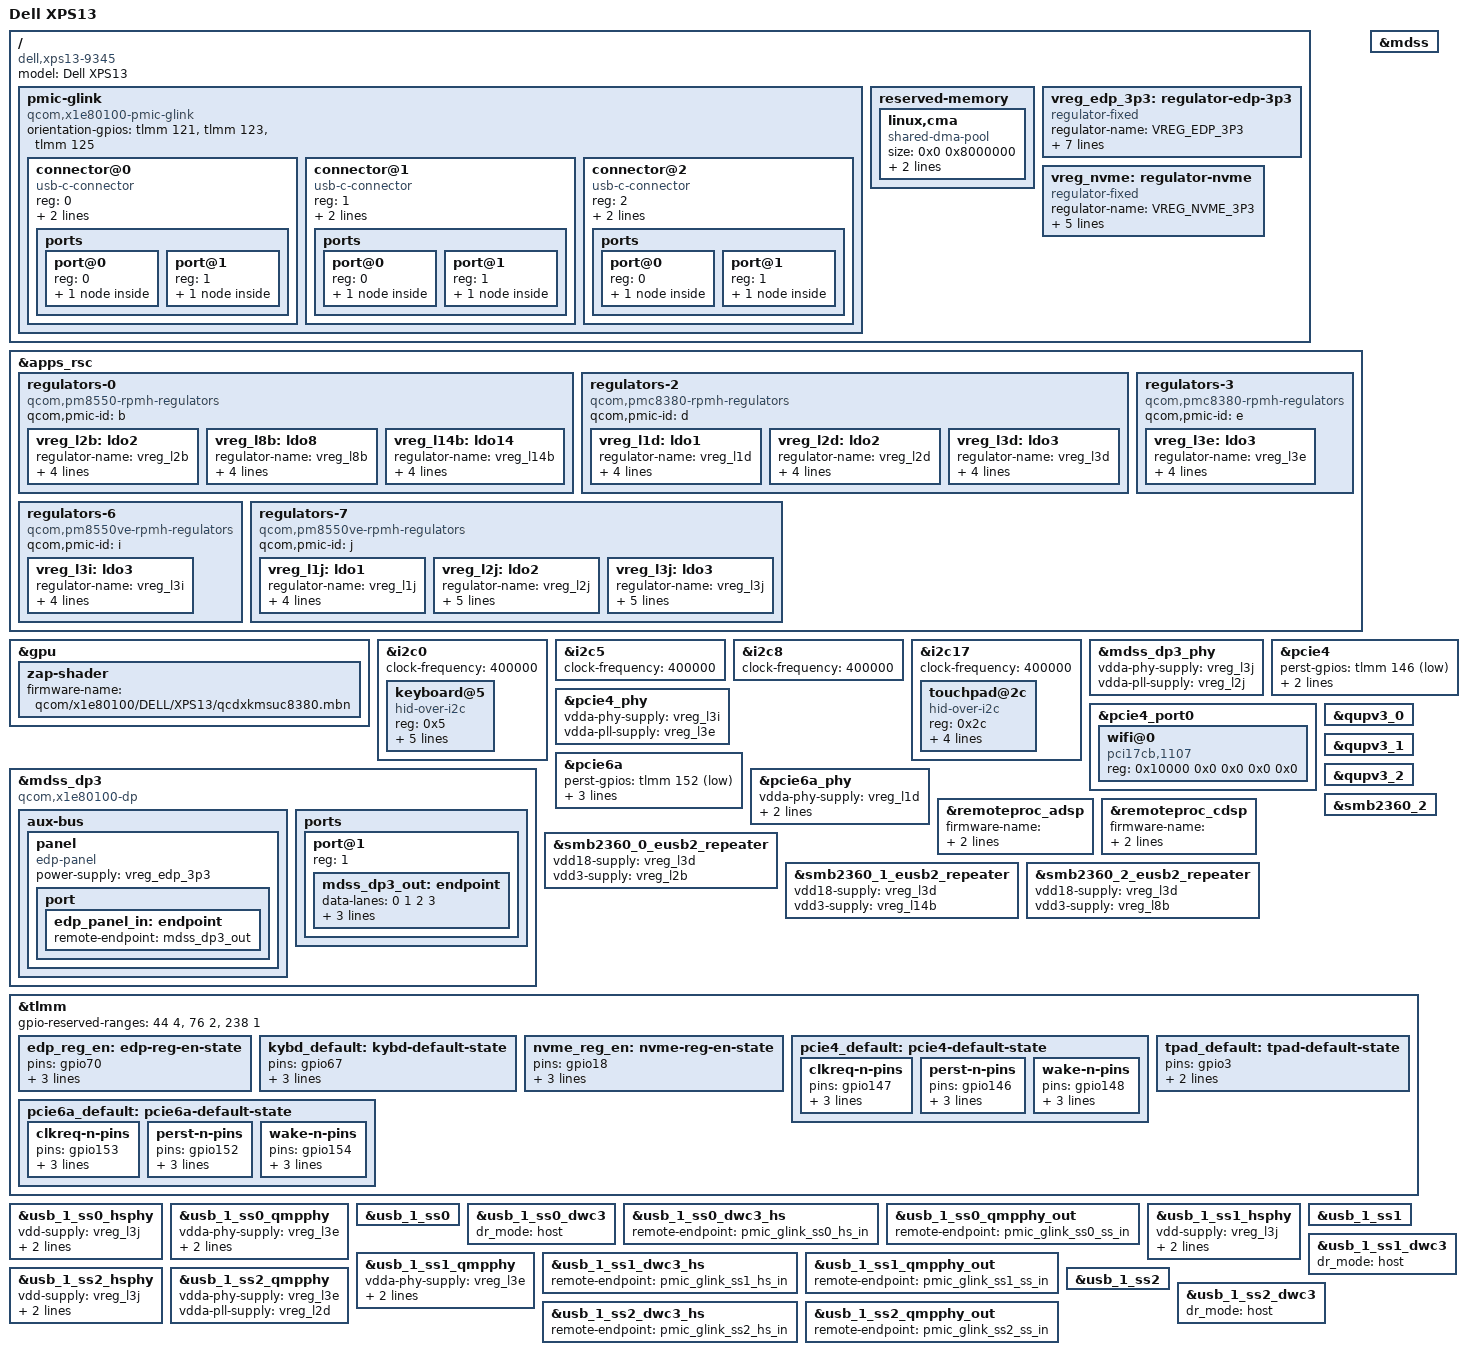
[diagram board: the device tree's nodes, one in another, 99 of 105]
// SPDX-License-Identifier: BSD-3-Clause
/*
 * Copyright (c) 2024 Qualcomm Innovation Center, Inc. All rights reserved.
 */

/dts-v1/;

#include <dt-bindings/gpio/gpio.h>
#include <dt-bindings/regulator/qcom,rpmh-regulator.h>

#include "x1e80100.dtsi"
#include "x1e80100-pmics.dtsi"

/ {
	model = "Dell XPS13";
	compatible = "dell,xps13-9345", "qcom,x1e80100";

	pmic-glink {
		compatible = "qcom,x1e80100-pmic-glink",
			     "qcom,sm8550-pmic-glink",
			     "qcom,pmic-glink";
		#address-cells = <1>;
		#size-cells = <0>;
		orientation-gpios = <&tlmm 121 GPIO_ACTIVE_HIGH>,
				    <&tlmm 123 GPIO_ACTIVE_HIGH>,
				    <&tlmm 125 GPIO_ACTIVE_HIGH>;

		/* Left-side rear port */
		connector@0 {
			compatible = "usb-c-connector";
			reg = <0>;
			power-role = "dual";
			data-role = "dual";

			ports {
				#address-cells = <1>;
				#size-cells = <0>;

				port@0 {
					reg = <0>;

					pmic_glink_ss0_hs_in: endpoint {
						remote-endpoint = <&usb_1_ss0_dwc3_hs>;
					};
				};

				port@1 {
					reg = <1>;

					pmic_glink_ss0_ss_in: endpoint {
						remote-endpoint = <&usb_1_ss0_qmpphy_out>;
					};
				};
			};
		};

		/* Left-side front port */
		connector@1 {
			compatible = "usb-c-connector";
			reg = <1>;
			power-role = "dual";
			data-role = "dual";

			ports {
				#address-cells = <1>;
				#size-cells = <0>;

				port@0 {
					reg = <0>;

					pmic_glink_ss1_hs_in: endpoint {
						remote-endpoint = <&usb_1_ss1_dwc3_hs>;
					};
				};

				port@1 {
					reg = <1>;

					pmic_glink_ss1_ss_in: endpoint {
						remote-endpoint = <&usb_1_ss1_qmpphy_out>;
					};
				};
			};
		};

		/* Right-side port */
		connector@2 {
			compatible = "usb-c-connector";
			reg = <2>;
			power-role = "dual";
			data-role = "dual";

			ports {
				#address-cells = <1>;
				#size-cells = <0>;

				port@0 {
					reg = <0>;

					pmic_glink_ss2_hs_in: endpoint {
						remote-endpoint = <&usb_1_ss2_dwc3_hs>;
					};
				};

				port@1 {
					reg = <1>;

					pmic_glink_ss2_ss_in: endpoint {
						remote-endpoint = <&usb_1_ss2_qmpphy_out>;
					};
				};
			};
		};
	};

	reserved-memory {
		linux,cma {
			compatible = "shared-dma-pool";
			size = <0x0 0x8000000>;
			reusable;
			linux,cma-default;
		};
	};

	vreg_edp_3p3: regulator-edp-3p3 {
		compatible = "regulator-fixed";

		regulator-name = "VREG_EDP_3P3";
		regulator-min-microvolt = <3300000>;
		regulator-max-microvolt = <3300000>;

		gpio = <&tlmm 70 GPIO_ACTIVE_HIGH>;
		enable-active-high;

		pinctrl-0 = <&edp_reg_en>;
		pinctrl-names = "default";

		regulator-always-on;
		regulator-boot-on;
	};

	vreg_nvme: regulator-nvme {
		compatible = "regulator-fixed";

		regulator-name = "VREG_NVME_3P3";
		regulator-min-microvolt = <3300000>;
		regulator-max-microvolt = <3300000>;

		gpio = <&tlmm 18 GPIO_ACTIVE_HIGH>;
		enable-active-high;

		pinctrl-0 = <&nvme_reg_en>;
		pinctrl-names = "default";
	};
};

&apps_rsc {
	regulators-0 {
		compatible = "qcom,pm8550-rpmh-regulators";
		qcom,pmic-id = "b";

		vreg_l2b: ldo2 {
			regulator-name = "vreg_l2b";
			regulator-min-microvolt = <3072000>;
			regulator-max-microvolt = <3100000>;
			regulator-initial-mode = <RPMH_REGULATOR_MODE_HPM>;
		};

		vreg_l8b: ldo8 {
			regulator-name = "vreg_l8b";
			regulator-min-microvolt = <3072000>;
			regulator-max-microvolt = <3072000>;
			regulator-initial-mode = <RPMH_REGULATOR_MODE_HPM>;
		};

		vreg_l14b: ldo14 {
			regulator-name = "vreg_l14b";
			regulator-min-microvolt = <3072000>;
			regulator-max-microvolt = <3072000>;
			regulator-initial-mode = <RPMH_REGULATOR_MODE_HPM>;
		};
	};

	regulators-2 {
		compatible = "qcom,pmc8380-rpmh-regulators";
		qcom,pmic-id = "d";

		vreg_l1d: ldo1 {
			regulator-name = "vreg_l1d";
			regulator-min-microvolt = <880000>;
			regulator-max-microvolt = <920000>;
			regulator-initial-mode = <RPMH_REGULATOR_MODE_HPM>;
		};

		vreg_l2d: ldo2 {
			regulator-name = "vreg_l2d";
			regulator-min-microvolt = <912000>;
			regulator-max-microvolt = <920000>;
			regulator-initial-mode = <RPMH_REGULATOR_MODE_HPM>;
		};

		vreg_l3d: ldo3 {
			regulator-name = "vreg_l3d";
			regulator-min-microvolt = <1800000>;
			regulator-max-microvolt = <1800000>;
			regulator-initial-mode = <RPMH_REGULATOR_MODE_HPM>;
		};
	};

	regulators-3 {
		compatible = "qcom,pmc8380-rpmh-regulators";
		qcom,pmic-id = "e";

		vreg_l3e: ldo3 {
			regulator-name = "vreg_l3e";
			regulator-min-microvolt = <1200000>;
			regulator-max-microvolt = <1200000>;
			regulator-initial-mode = <RPMH_REGULATOR_MODE_HPM>;
		};
	};

	regulators-6 {
		compatible = "qcom,pm8550ve-rpmh-regulators";
		qcom,pmic-id = "i";

		vreg_l3i: ldo3 {
			regulator-name = "vreg_l3i";
			regulator-min-microvolt = <880000>;
			regulator-max-microvolt = <920000>;
			regulator-initial-mode = <RPMH_REGULATOR_MODE_HPM>;
		};
	};

	regulators-7 {
		compatible = "qcom,pm8550ve-rpmh-regulators";
		qcom,pmic-id = "j";

		vreg_l1j: ldo1 {
			regulator-name = "vreg_l1j";
			regulator-min-microvolt = <880000>;
			regulator-max-microvolt = <920000>;
			regulator-initial-mode = <RPMH_REGULATOR_MODE_HPM>;
		};

		vreg_l2j: ldo2 {
			regulator-name = "vreg_l2j";
			regulator-min-microvolt = <1200000>;
			regulator-max-microvolt = <1200000>;
			regulator-initial-mode = <RPMH_REGULATOR_MODE_HPM>;
			regulator-always-on; /* display? */
		};

		vreg_l3j: ldo3 {
			regulator-name = "vreg_l3j";
			regulator-min-microvolt = <880000>;
			regulator-max-microvolt = <920000>;
			regulator-initial-mode = <RPMH_REGULATOR_MODE_HPM>;
			regulator-always-on; /* display? */
		};
	};
};

&gpu {
	status = "okay";

	zap-shader {
		firmware-name = "qcom/x1e80100/DELL/XPS13/qcdxkmsuc8380.mbn";
	};
};

&i2c0 {
	clock-frequency = <400000>;

	status = "okay";

	keyboard@5 {
		compatible = "hid-over-i2c";
		reg = <0x5>;

		hid-descr-addr = <0x20>;
		interrupts-extended = <&tlmm 67 IRQ_TYPE_LEVEL_LOW>;

		pinctrl-0 = <&kybd_default>;
		pinctrl-names = "default";

		wakeup-source;
	};
};

&i2c5 {
	clock-frequency = <400000>;

	status = "okay";

	/* 3b */
};

&i2c8 {
	clock-frequency = <400000>;

	status = "okay";

	/* 10 */
};

&i2c17 {
	clock-frequency = <400000>;

	status = "okay";

	touchpad@2c {
		compatible = "hid-over-i2c";
		reg = <0x2c>;

		hid-descr-addr = <0x20>;
		interrupts-extended = <&tlmm 3 IRQ_TYPE_LEVEL_LOW>;

		pinctrl-0 = <&tpad_default>;
		pinctrl-names = "default";

		wakeup-source;
	};
};

&mdss {
	status = "okay";
};

&mdss_dp3 {
	compatible = "qcom,x1e80100-dp";
	/delete-property/ #sound-dai-cells;

	status = "okay";

	aux-bus {
		panel {
			compatible = "edp-panel";
			power-supply = <&vreg_edp_3p3>;

			port {
				edp_panel_in: endpoint {
					remote-endpoint = <&mdss_dp3_out>;
				};
			};
		};
	};

	ports {
		port@1 {
			reg = <1>;

			mdss_dp3_out: endpoint {
				data-lanes = <0 1 2 3>;
				link-frequencies = /bits/ 64 <1620000000 2700000000 5400000000 8100000000>;

				remote-endpoint = <&edp_panel_in>;
			};
		};
	};
};

&mdss_dp3_phy {
	vdda-phy-supply = <&vreg_l3j>;
	vdda-pll-supply = <&vreg_l2j>;

	status = "okay";
};

&pcie4 {
	perst-gpios = <&tlmm 146 GPIO_ACTIVE_LOW>;
	wake-gpios = <&tlmm 148 GPIO_ACTIVE_LOW>;

	pinctrl-0 = <&pcie4_default>;
	pinctrl-names = "default";

	status = "okay";
};

&pcie4_phy {
	vdda-phy-supply = <&vreg_l3i>;
	vdda-pll-supply = <&vreg_l3e>;

	status = "okay";
};

&pcie4_port0 {
	wifi@0 {
		compatible = "pci17cb,1107";
		reg = <0x10000 0x0 0x0 0x0 0x0>;
	};
};

&pcie6a {
	perst-gpios = <&tlmm 152 GPIO_ACTIVE_LOW>;
	wake-gpios = <&tlmm 154 GPIO_ACTIVE_LOW>;

	vddpe-3v3-supply = <&vreg_nvme>;

	pinctrl-0 = <&pcie6a_default>;
	pinctrl-names = "default";

	status = "okay";
};

&pcie6a_phy {
	vdda-phy-supply = <&vreg_l1d>;
	vdda-pll-supply = <&vreg_l2j>;
	vdda-qref-supply = <&vreg_l3j>;

	status = "okay";
};

&qupv3_0 {
	status = "okay";
};

&qupv3_1 {
	status = "okay";
};

&qupv3_2 {
	status = "okay";
};

&remoteproc_adsp {
	firmware-name = "qcom/x1e80100/DELL/XPS13/qcadsp8380.mbn",
			"qcom/x1e80100/DELL/XPS13/adsp_dtbs.elf";
	status = "okay";
};

&remoteproc_cdsp {
	firmware-name = "qcom/x1e80100/DELL/XPS13/qccdsp8380.mbn",
			"qcom/x1e80100/DELL/XPS13/cdsp_dtbs.elf";

	status = "okay";
};

&smb2360_0_eusb2_repeater {
	vdd18-supply = <&vreg_l3d>;
	vdd3-supply = <&vreg_l2b>;
};

&smb2360_1_eusb2_repeater {
	vdd18-supply = <&vreg_l3d>;
	vdd3-supply = <&vreg_l14b>;
};

&smb2360_2 {
	status = "okay";
};

&smb2360_2_eusb2_repeater {
	vdd18-supply = <&vreg_l3d>;
	vdd3-supply = <&vreg_l8b>;
};

&tlmm {
	gpio-reserved-ranges = <44 4>, /* QUP1 SE3 */
			       <76 2>, /* QUP2 SE3 */
			       <238 1>; /* UFS Reset */

	edp_reg_en: edp-reg-en-state {
		pins = "gpio70";
		function = "gpio";
		drive-strength = <16>;
		bias-disable;
	};

	kybd_default: kybd-default-state {
		pins = "gpio67";
		function = "gpio";
		drive-strength = <2>;
		bias-pull-up;
	};

	nvme_reg_en: nvme-reg-en-state {
		pins = "gpio18";
		function = "gpio";
		drive-strength = <2>;
		bias-disable;
	};

	pcie4_default: pcie4-default-state {
		clkreq-n-pins {
			pins = "gpio147";
			function = "pcie4_clk";
			drive-strength = <2>;
			bias-pull-up;
		};

		perst-n-pins {
			pins = "gpio146";
			function = "gpio";
			drive-strength = <2>;
			bias-disable;
		};

		wake-n-pins {
			pins = "gpio148";
			function = "gpio";
			drive-strength = <2>;
			bias-pull-up;
		};
	};

	pcie6a_default: pcie6a-default-state {
		clkreq-n-pins {
			pins = "gpio153";
			function = "pcie6a_clk";
			drive-strength = <2>;
			bias-pull-up;
		};

		perst-n-pins {
			pins = "gpio152";
			function = "gpio";
			drive-strength = <2>;
			bias-disable;
		};

		wake-n-pins {
			pins = "gpio154";
			function = "gpio";
			drive-strength = <2>;
			bias-pull-up;
		};
	};

	tpad_default: tpad-default-state {
		pins = "gpio3";
		function = "gpio";
		bias-disable;
	};
};

&usb_1_ss0_hsphy {
	vdd-supply = <&vreg_l3j>;
	vdda12-supply = <&vreg_l2j>;

	phys = <&smb2360_0_eusb2_repeater>;

	status = "okay";
};

&usb_1_ss0_qmpphy {
	vdda-phy-supply = <&vreg_l3e>;
	vdda-pll-supply = <&vreg_l1j>;

	orientation-switch;

	status = "okay";
};

&usb_1_ss0 {
	status = "okay";
};

&usb_1_ss0_dwc3 {
	dr_mode = "host";
};

&usb_1_ss0_dwc3_hs {
	remote-endpoint = <&pmic_glink_ss0_hs_in>;
};

&usb_1_ss0_qmpphy_out {
	remote-endpoint = <&pmic_glink_ss0_ss_in>;
};

&usb_1_ss1_hsphy {
	vdd-supply = <&vreg_l3j>;
	vdda12-supply = <&vreg_l2j>;

	phys = <&smb2360_1_eusb2_repeater>;

	status = "okay";
};

&usb_1_ss1_qmpphy {
	vdda-phy-supply = <&vreg_l3e>;
	vdda-pll-supply = <&vreg_l2d>;

	orientation-switch;

	status = "okay";
};

&usb_1_ss1 {
	status = "okay";
};

&usb_1_ss1_dwc3 {
	dr_mode = "host";
};

&usb_1_ss1_dwc3_hs {
	remote-endpoint = <&pmic_glink_ss1_hs_in>;
};

&usb_1_ss1_qmpphy_out {
	remote-endpoint = <&pmic_glink_ss1_ss_in>;
};

&usb_1_ss2_hsphy {
	vdd-supply = <&vreg_l3j>;
	vdda12-supply = <&vreg_l2j>;

	phys = <&smb2360_2_eusb2_repeater>;

	status = "okay";
};

&usb_1_ss2_qmpphy {
	vdda-phy-supply = <&vreg_l3e>;
	vdda-pll-supply = <&vreg_l2d>;

	status = "okay";
};

&usb_1_ss2 {
	status = "okay";
};

&usb_1_ss2_dwc3 {
	dr_mode = "host";
};

&usb_1_ss2_dwc3_hs {
	remote-endpoint = <&pmic_glink_ss2_hs_in>;
};

&usb_1_ss2_qmpphy_out {
	remote-endpoint = <&pmic_glink_ss2_ss_in>;
};
